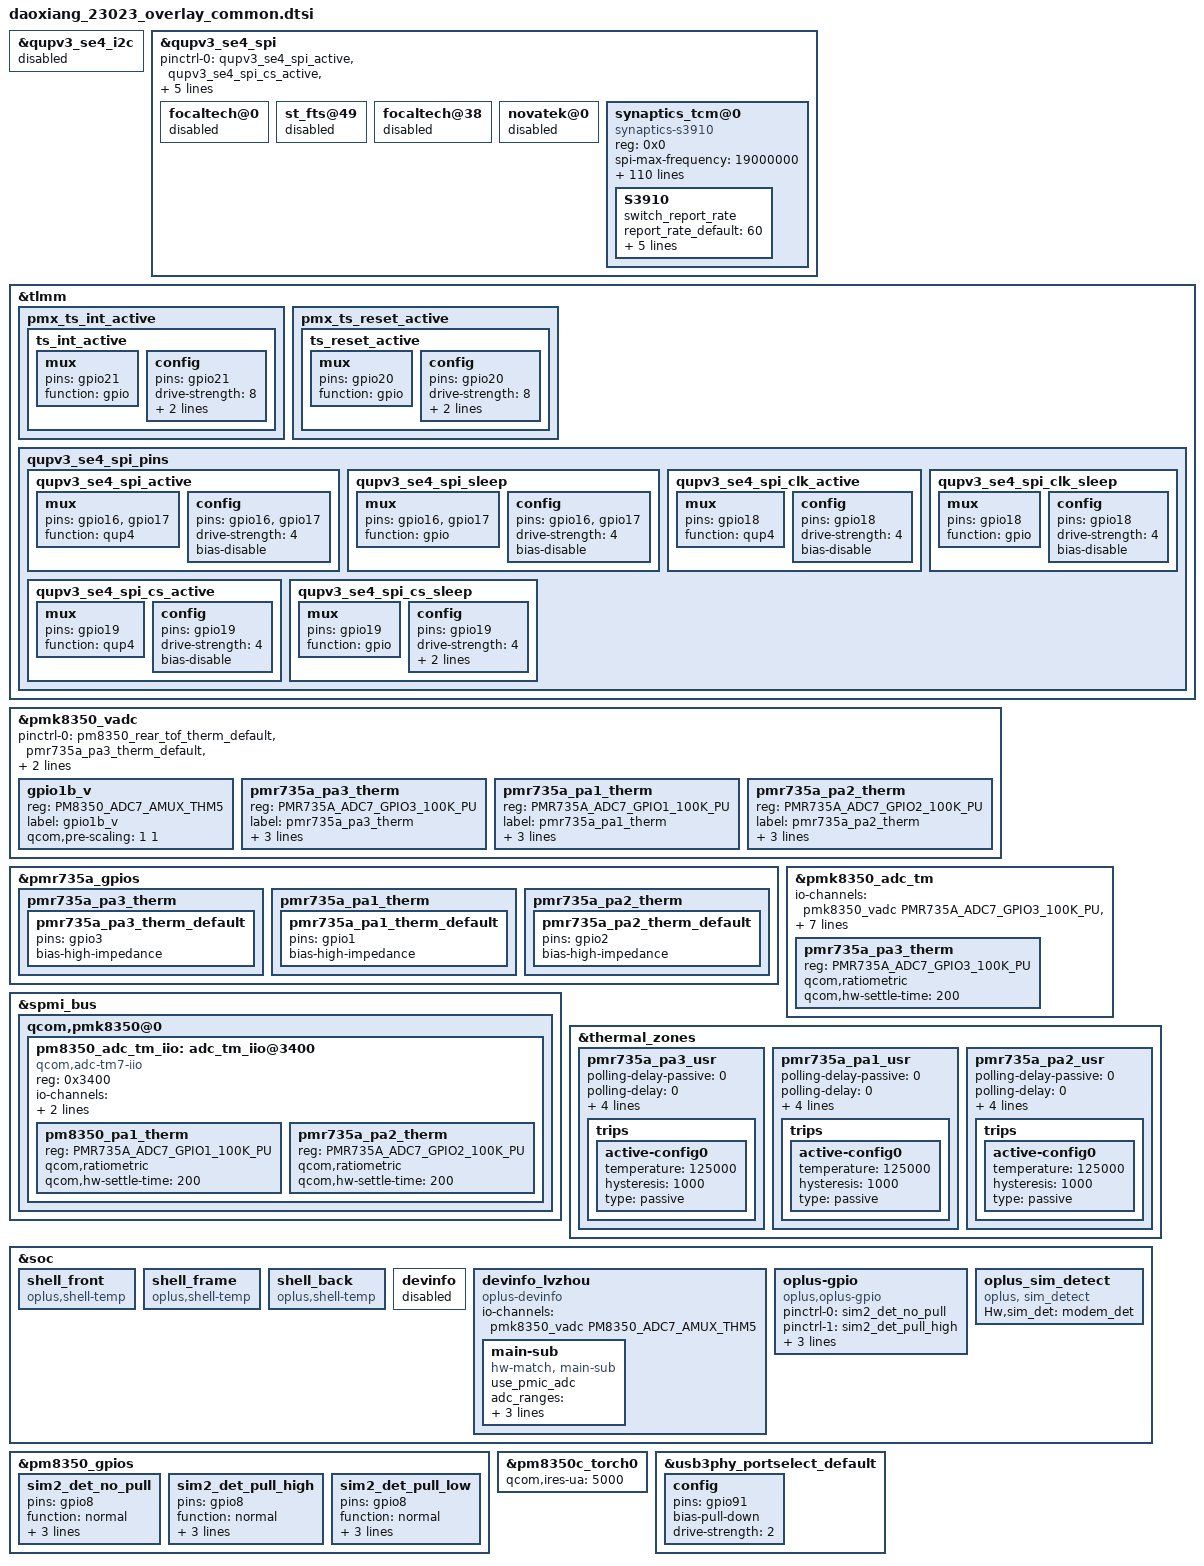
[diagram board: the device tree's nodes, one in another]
&qupv3_se4_i2c {
    status = "disabled";
};

&qupv3_se4_spi{
    /delete-property/ pinctrl-0;
    /delete-property/ pinctrl-1;
    pinctrl-0 = <&qupv3_se4_spi_active &qupv3_se4_spi_cs_active &qupv3_se4_spi_clk_active>;
    pinctrl-1 = <&qupv3_se4_spi_sleep &qupv3_se4_spi_cs_sleep &qupv3_se4_spi_clk_sleep>;
};

&tlmm {
    pmx_ts_int_active {
        ts_int_active: ts_int_active {
            mux {
                pins = "gpio21";
                function = "gpio";
            };

            config {
                pins = "gpio21";
                drive-strength = <8>;
                bias-disable;
                input-enable;
            };
        };
    };

    pmx_ts_reset_active {
        ts_reset_active: ts_reset_active {
            mux {
                pins = "gpio20";
                function = "gpio";
            };

            config {
                pins = "gpio20";
                drive-strength = <8>;
                output-low;
                bias-disable;
            };
        };
    };
};

&qupv3_se4_spi {
    status = "ok";
    #address-cells = <1>;
        #size-cells = <0>;

    qcom,spi-touch-active = "synaptics-s3910";

    /delete-node/ focaltech@0;
        focaltech@0 {
                status = "disabled";
        };
    st_fts@49 {
        status = "disabled";
    };
    focaltech@38 {
        status = "disabled";
    };
    novatek@0 {
        status = "disabled";
    };
    synaptics_tcm@0{
        status = "ok";
        compatible = "synaptics-s3910";
        reg = <0x0>;
        spi-max-frequency = <19000000>;
        chip-name = "S3910";

        /* Interrupt && Irq-gpio */
        interrupt-parent = <&tlmm>;
        interrupts = <21 0x2008>;
        irq-gpio = <&tlmm 21 0x2008>;
        reset-gpio = <&tlmm 20 0x1>;

        /* Power Config */
        /* enable2v8_gpio = <&tlmm 186 0x1>;*/
        /* enable1v8_gpio = <&tlmm 97 0x1>; */
	vdd_2v8-supply = <&pm8350c_l11>;
        vcc_1v8-supply = <&L4H>;
        vdd_2v8_volt = <3000000>;

        /* Other HW Resource */

        pinctrl-names = "default";
        pinctrl-0 = <&ts_int_active &ts_reset_active>;

        touchpanel,max-num-support = <10>;
        touchpanel,tx-rx-num = <16 36>;
        touchpanel,panel-coords = <12400 27720>;
        touchpanel,display-coords = <1240 2772>;
        touchpanel,touchmajor-limit = <128 216>;
        touchpanel,elimination-range = <20 200 200>;
        touchpanel,int-mode = <1>; /*0: interrupt and disable, 1:interrupt and not disable*/
        touchpanel,smooth-level = <0 1 2 4 7 9>;
        touchpanel,smooth-level-charging = <0 2 4 7 8 9>;
        touchpanel,sensitive-level = <0 70 55 50 25 10>;
        touchpanel,single-optimized-time = <8>;
        touchpanel,high-frame-rate-time = <60>;

        project_id = <23023>;
        vid_len = <2>;
        touchpanel,tp-index = <0>;
        panel_type = <3>;
        // type of tp_dev ,TP-SAMSUNG = 8; BOE = 3; TIANMA = 7;
        platform_support_project = <23023>;
        platform_support_project_dir = <23023>;
        platform_support_project_commandline = "mdss_dsi_panel_BF185_P_3_A0001_dsc_cmd";

        prevention,curved_screen_V2;
        prevention,grip_disable_level = <6>;
        prevention,updelay_time_ms = <30>;
        prevention,makeup_cnt_weight = <4 1 2 2 2>;
        prevention,large_corner_range = <1380 3400>;
        prevention,large_corner_judge_condition = <500 300 1200 7 7>;
        prevention,trx_reject_condition = <8 7 7>;
        prevention,trx_strict_reject_condition = <8 6 6>;
        prevention,large_judge_time_ms = <500 50 30>;
        prevention,large_exit_condition = <8 8 2>;
        prevention,single_channel_width = <320 320>;
        prevention,normal_tap_condition = <10 350>;
        prevention,long_edge_condition = <179 90 120 80>;
        prevention,long_strict_edge_condition = <160 60>;
        prevention,long_fingerhold_condition = <70 6 4 4>;
        prevention,short_edge_condition = <179 90 120 80>;
        prevention,short_strict_edge_condition = <160 60>;
        prevention,large_strict_exit_condition = <6 6>;
        prevention,top_corner_config = <250 750 1000>;
        prevention,edge_swipe_config = <340 1380>;

        prevention,curved_screen_V4;
        prevention,long_eliminate_point_type = <2 12400 9240 240 27720 300 1>;
        prevention,long_fingerhold_condition2 = <700 2000 0 0>;
        prevention,top_corner_config2 =<3 80 600 1500 0>;
        prevention,hor_long_top_corner_config =<300 2000 0 0>;
        prevention,top_middle_config =<12400 1000 1000 0>;
        prevention,corner_eliminate_point_type =<0 1380 2270 1>;
        prevention,finger_hold_differ_size = <1 0 400 300>;
        prevention,finger_hold_max_rx_exit_distance = <5 350 2300>;
        prevention,max_rx_exit_distance = <1 5 150 350 2000>;
        prevention,dynamic_finger_hold_exit_distance = <1 350 2300 450>;
        prevention,edge_sliding_matched_support = <1 250 3 0>;


        //grip v4.2 reclining mode
        prevention,reclining_mode_support = <1>;
        prevention,long_eliminate_point_type_recli = <2 12400 9240 240 27720 500 1>;
        prevention,finger_hold_differ_size_recli = <1 0 400 400>;
        prevention,finger_hold_max_rx_exit_distance_recli = <5 350 2300>;
        prevention,max_rx_exit_distance_recli = <1 5 100 350 2300>;
        prevention,dynamic_finger_hold_exit_distance_recli = <1 350 2300 450>;
        prevention,edge_sliding_matched_support_recli = <1 200 3 0>;
        prevention,long_edge_condition_recli = <179 90 120 80>;

        /* SW Support Feature Control */
        black_gesture_support;
        sportify_aod_gesture_support;
        pressure_report_support;
        charger_pump_support;
        game_switch_support;
        smart_gesture_support;
        fw_update_app_support;
        fingerprint_underscreen_support;
        freq_hop_simulate_support;
        report_flow_unlock_support;
        screenoff_fingerprint_info_support;
        irq_need_dev_resume_ok;
        enable_point_auto_change;
        kernel_grip_support;
        exception_upload_support;
        //grip_no_driver_support;
        health_monitor_support;
        black_gesture_indep_support;
        snr_read_support;
        palm_to_sleep_support;
        tp_data_record_support;
        fingerprint_not_report_in_suspend;
        /*
         *Virtual Key Config:
         *1:touchpanel,button-type: <virtualkey_type  supportted_button-map>
         *virtualkey_type:
         *Type 1: using board_properties
         *Type 2: using same IC (button zone&& touch zone are seprate)
         *Type 3: using diffrent IC (button zone&& touch zone are seprate)
         *Type 4: No need of virtual key process
         *supportted_button-map:select|menu|home|back
         *
         *2:touchpanel,button-map
         *type (X1,Y1)(X2,Y2)(X3,Y3)(Width_X,Hight_Y)--Only when button-type is 0
         */
        touchpanel,button-type = <4>;
        touchpanel.button-TRx = <0 0>;

        S3910 {
		switch_report_rate;
		report_rate_default = <60>;
		report_rate_game_value = <0x03>;
		fps_report_rate = <60 2 90 3 120 3>;//1:360Hz 2:125Hz 3:240Hz
		fwupdate_bootloader = <1>;
		default_gesture_mask = <8191>;
		normal_config_version = <2>;
        };
    };
};
&tlmm {
    qupv3_se4_spi_pins: qupv3_se4_spi_pins {
        qupv3_se4_spi_active: qupv3_se4_spi_active {
            mux {
                pins = "gpio16", "gpio17";
                function = "qup4";
            };

            config {
                pins = "gpio16", "gpio17";
                drive-strength = <4>;
                bias-disable;
            };
        };

        qupv3_se4_spi_sleep: qupv3_se4_spi_sleep {
            mux {
                pins = "gpio16", "gpio17";
                function = "gpio";
            };

            config {
                pins = "gpio16", "gpio17";
                drive-strength = <4>;
                bias-disable;
            };
        };

	qupv3_se4_spi_clk_active: qupv3_se4_spi_clk_active {
            mux {
                pins = "gpio18";
                function = "qup4";
            };

            config {
                pins = "gpio18";
                drive-strength = <4>;
                bias-disable;
            };
        };

        qupv3_se4_spi_clk_sleep: qupv3_se4_spi_clk_sleep {
            mux {
                pins = "gpio18";
                function = "gpio";
            };

            config {
                pins = "gpio18";
                drive-strength = <4>;
                bias-disable;
            };
        };

        qupv3_se4_spi_cs_active: qupv3_se4_spi_cs_active {
            mux {
                pins = "gpio19";
                function = "qup4";
            };

            config {
                pins ="gpio19";
                drive-strength = <4>;
                bias-disable;
            };
        };
        qupv3_se4_spi_cs_sleep: qupv3_se4_spi_cs_sleep {
            mux {
                pins = "gpio19";
                function = "gpio";
            };

            config {
                pins = "gpio19";
                drive-strength = <4>;
                bias-disable;
                output-high;
            };
        };
    };
//#endif /*OPLUS_FEATURE_TP_BASIC*/
};

&pmk8350_vadc {
    gpio1b_v {
        reg = <PM8350_ADC7_AMUX_THM5>;
        label = "gpio1b_v";
        qcom,pre-scaling = <1 1>;
    };
};

//gqw,2022/07/20, add 4g pa to thermal ntc start
//wuchanghua, 2023/0118, add wifi pa to thermal zone
&pmk8350_vadc {
	pinctrl-names = "default";
	pinctrl-0 = <&pm8350_rear_tof_therm_default &pmr735a_pa3_therm_default &pmr735a_pa1_therm_default &pmr735a_pa2_therm_default>;

	/delete-node/ pm8350_rear_tof_therm;

	pmr735a_pa3_therm {
		reg = <PMR735A_ADC7_GPIO3_100K_PU>;
		label = "pmr735a_pa3_therm";
		qcom,ratiometric;
		qcom,hw-settle-time = <200>;
		qcom,pre-scaling = <1 1>;
	};

	pmr735a_pa1_therm {
		reg = <PMR735A_ADC7_GPIO1_100K_PU>;
		label = "pmr735a_pa1_therm";
		qcom,ratiometric;
		qcom,hw-settle-time = <200>;
		qcom,pre-scaling = <1 1>;
	};

	pmr735a_pa2_therm {
		reg = <PMR735A_ADC7_GPIO2_100K_PU>;
		label = "pmr735a_pa2_therm";
		qcom,ratiometric;
		qcom,hw-settle-time = <200>;
		qcom,pre-scaling = <1 1>;
	};
};

&pmr735a_gpios {
	pmr735a_pa3_therm {
         pmr735a_pa3_therm_default: pmr735a_pa3_therm_default {
               pins = "gpio3";
               bias-high-impedance;
         };
      };

	pmr735a_pa1_therm {
		pmr735a_pa1_therm_default: pmr735a_pa1_therm_default {
			pins = "gpio1";
			bias-high-impedance;
		};
	};

	pmr735a_pa2_therm {
         pmr735a_pa2_therm_default: pmr735a_pa2_therm_default {
               pins = "gpio2";
               bias-high-impedance;
         };
      };
};

&pmk8350_adc_tm {
	io-channels = <&pmk8350_vadc PMR735A_ADC7_GPIO3_100K_PU>,
			<&pmk8350_vadc PM8350_ADC7_AMUX_THM1_100K_PU>,
			<&pmk8350_vadc PM8350_ADC7_AMUX_THM2_100K_PU>,
			<&pmk8350_vadc PM8350_ADC7_AMUX_THM3_100K_PU>,
			<&pmk8350_vadc PM8350_ADC7_AMUX_THM4_100K_PU>,
			<&pmk8350_vadc PM8350B_ADC7_AMUX_THM4_100K_PU>,
			<&pmk8350_vadc PM8350B_ADC7_GPIO2_100K_PU>,
			<&pmk8350_vadc PMK8350_ADC7_AMUX_THM1_100K_PU>;

	/delete-node/ pm8350_rear_tof_therm;

	pmr735a_pa3_therm {
		reg = <PMR735A_ADC7_GPIO3_100K_PU>;
		qcom,ratiometric;
		qcom,hw-settle-time = <200>;
	};
};

&spmi_bus {
	qcom,pmk8350@0 {
		pm8350_adc_tm_iio: adc_tm_iio@3400 {
			/* Alternate ADC_TM DT node */
			compatible = "qcom,adc-tm7-iio";
			/* With this entry, a feature-reduced
			version of the driver is initialized (only
			thermistor reads, no interrupt functionality
			for exposed thermistors) */
			reg = <0x3400>;
			#thermal-sensor-cells = <1>;
			#address-cells = <1>;
			#size-cells = <0>;
			io-channels = <&pmk8350_vadc PMR735A_ADC7_GPIO1_100K_PU>,
						<&pmk8350_vadc PMR735A_ADC7_GPIO2_100K_PU>;
			/* Similar to io-channels in actual ADC_TM node,
			for reading thermistor temperature from
			VADC */

			pm8350_pa1_therm {
				reg = <PMR735A_ADC7_GPIO1_100K_PU>;
				qcom,ratiometric;
				qcom,hw-settle-time = <200>;
			};

			pmr735a_pa2_therm {
				reg = <PMR735A_ADC7_GPIO2_100K_PU>;
				qcom,ratiometric;
				qcom,hw-settle-time = <200>;
			};

		};
	};
};

&thermal_zones {

	/delete-node/ pm8350_rear_tof_therm;

	pmr735a_pa3_usr {
		polling-delay-passive = <0>;
		polling-delay = <0>;
		thermal-governor = "user_space";
		thermal-sensors = <&pmk8350_adc_tm PMR735A_ADC7_GPIO3_100K_PU>;
		wake-capable-sensor;
		trips {
			active-config0 {
				temperature = <125000>;
				hysteresis = <1000>;
				type = "passive";
			};
		};
	};

	pmr735a_pa1_usr {
		polling-delay-passive = <0>;
		polling-delay = <0>;
		thermal-governor = "user_space";
		thermal-sensors = <&pm8350_adc_tm_iio PMR735A_ADC7_GPIO1_100K_PU>;
		wake-capable-sensor;
		trips {
			active-config0 {
				temperature = <125000>;
				hysteresis = <1000>;
				type = "passive";
			};
		};
	};

	pmr735a_pa2_usr {
		polling-delay-passive = <0>;
		polling-delay = <0>;
		thermal-governor = "user_space";
		thermal-sensors = <&pm8350_adc_tm_iio PMR735A_ADC7_GPIO2_100K_PU>;
		wake-capable-sensor;
		trips {
			active-config0 {
				temperature = <125000>;
				hysteresis = <1000>;
				type = "passive";
			};
		};
	};
};
//gqw 2022/07/20, add 4g pa to thermal ntc end

//gqw 2022/07/20, add for thermal horae start
&soc {
	shell_front {
		compatible = "oplus,shell-temp";
	};

	shell_frame {
		compatible = "oplus,shell-temp";
	};

	shell_back {
		compatible = "oplus,shell-temp";
	};
};
//gqw 2022/07/20, add for thermal horae end

&soc {
    devinfo {
        status = "disabled";
    };

    devinfo_lvzhou {
        compatible = "oplus-devinfo";

        //pinctrl-names = "default", "sleep", "active", "idle";
        //pinctrl-0 = <&hw_pins_default>;
        //pinctrl-1 = <&aboard_pin_gpio0_sleep>;
        //pinctrl-2 = <&aboard_pin_gpio0_active>;
        //pinctrl-3 = <&aboard_pin_gpio0_idle>;

        io-channels= <&pmk8350_vadc PM8350_ADC7_AMUX_THM5>;
        io-channel-names= "vph_pwr_voltage_sub";

        // lvzhou A1 platelets
        main-sub {
            compatible = "hw-match, main-sub";
            use_pmic_adc;
            adc_ranges = <0 80
                    81 180
                    181 300
                    301 420
                    421 550
                    551 650
                    651 760
                    761 850
                    851 950
                    951 1050
                    1051 1150
                    1151 1300>;
            aboard-patterns = <0>;  // defult

            /*main board*/
            match-projects = <23023>;
        };
    };
	//#ifdef OPLUS_FEATRUE_DUAL_SIM_DETECT
	oplus-gpio {
		compatible = "oplus,oplus-gpio";
		pinctrl-names = "sim2_det_no_pull", "sim2_det_pull_high", "sim2_det_pull_low";
		pinctrl-0 = <&sim2_det_no_pull>;
		pinctrl-1 = <&sim2_det_pull_high>;
		pinctrl-2 = <&sim2_det_pull_low>;
		oplus,oplus-sim2-det = <&pm8350_gpios 8 0>;
		oplus,uim-reset-pin = "modem_solution";
	};
	oplus_sim_detect {
		compatible = "oplus, sim_detect";
		Hw,sim_det = "modem_det";
	};
    //#endif /* OPLUS_FEATRUE_DUAL_SIM_DETECT */
};

&pm8350_gpios {
	//#ifdef OPLUS_FEATRUE_DUAL_SIM_DETECT
	sim2_det_no_pull: sim2_det_no_pull {
			pins = "gpio8";
			function = "normal";
			input-enable;
			power-source = <1>;
			bias-disable;
	};

	sim2_det_pull_high: sim2_det_pull_high {
			pins = "gpio8";
			function = "normal";
			input-enable;
			power-source = <1>;
			bias-pull-up;
	};

	sim2_det_pull_low: sim2_det_pull_low {
			pins = "gpio8";
			function = "normal";
			input-enable;
			power-source = <1>;
			bias-pull-down;
	};
	//#endif OPLUS_FEATRUE_DUAL_SIM_DETECT
};

&pm8350c_torch0 {
	qcom,ires-ua = <5000>;
};

//Add to change cc-out gpio pull down
&usb3phy_portselect_default {
	config {
		pins = "gpio91";
		bias-pull-down;
		drive-strength = <2>;
	};
};
